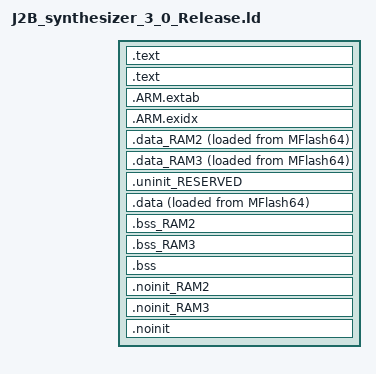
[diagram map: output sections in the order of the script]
/*
 * GENERATED FILE - DO NOT EDIT
 * (c) Code Red Technologies Ltd, 2008-${year}
 * (c) NXP Semiconductors 2013-${year}
 * Generated linker script file for 2015
 * Created from LPC1347 (Wed May 06 22:53:42 CEST 2015)
 * By generic_c.ld on LPCXpresso v7.0.2 [Build 102] [2014-03-11] 
 */


INCLUDE "J2B_synthesizer_3_0_Release_lib.ld"
INCLUDE "J2B_synthesizer_3_0_Release_mem.ld"

ENTRY(ResetISR)

SECTIONS
{

    /* MAIN TEXT SECTION */    
    .text : ALIGN(4)
    {
        FILL(0xff)
        __vectors_start__ = ABSOLUTE(.) ;
        KEEP(*(.isr_vector))
        
        /* Global Section Table */
        . = ALIGN(4) ;
        __section_table_start = .;
        __data_section_table = .;
        LONG(LOADADDR(.data));
        LONG(    ADDR(.data));
        LONG(  SIZEOF(.data));
        LONG(LOADADDR(.data_RAM2));
        LONG(    ADDR(.data_RAM2));
        LONG(  SIZEOF(.data_RAM2));
        LONG(LOADADDR(.data_RAM3));
        LONG(    ADDR(.data_RAM3));
        LONG(  SIZEOF(.data_RAM3));
        __data_section_table_end = .;
        __bss_section_table = .;
        LONG(    ADDR(.bss));
        LONG(  SIZEOF(.bss));
        LONG(    ADDR(.bss_RAM2));
        LONG(  SIZEOF(.bss_RAM2));
        LONG(    ADDR(.bss_RAM3));
        LONG(  SIZEOF(.bss_RAM3));
        __bss_section_table_end = .;
        __section_table_end = . ;
        /* End of Global Section Table */
        

        *(.after_vectors*)
        
    } >MFlash64
    
    .text : ALIGN(4)    
    {
         *(.text*)
        *(.rodata .rodata.* .constdata .constdata.*)
        . = ALIGN(4);
        
    } > MFlash64

    /*
     * for exception handling/unwind - some Newlib functions (in common
     * with C++ and STDC++) use this. 
     */
    .ARM.extab : ALIGN(4)
    {
    	*(.ARM.extab* .gnu.linkonce.armextab.*)
    } > MFlash64
    __exidx_start = .;
    
    .ARM.exidx : ALIGN(4)
    {
    	*(.ARM.exidx* .gnu.linkonce.armexidx.*)
    } > MFlash64
    __exidx_end = .;
    
    _etext = .;
        
    
    /* DATA section for RamUsb2 */
    .data_RAM2 : ALIGN(4)
    {
       FILL(0xff)
       *(.ramfunc.$RAM2)
    	*(.data.$RAM2*)
    	*(.data.$RamUsb2*)
       . = ALIGN(4) ;
    } > RamUsb2 AT>MFlash64
    
    /* DATA section for RamPeriph2 */
    .data_RAM3 : ALIGN(4)
    {
       FILL(0xff)
       *(.ramfunc.$RAM3)
    	*(.data.$RAM3*)
    	*(.data.$RamPeriph2*)
       . = ALIGN(4) ;
    } > RamPeriph2 AT>MFlash64
    
    /* MAIN DATA SECTION */
    

    .uninit_RESERVED : ALIGN(4)
    {
        KEEP(*(.bss.$RESERVED*))
        . = ALIGN(4) ;
        _end_uninit_RESERVED = .;
    } > RamLoc8

	
	/* Main DATA section (RamLoc8) */
	.data : ALIGN(4)
	{
	   FILL(0xff)
	   _data = . ;
	   *(vtable)
	   *(.ramfunc*)
	   *(.data*)
	   . = ALIGN(4) ;
	   _edata = . ;
	} > RamLoc8 AT>MFlash64

    /* BSS section for RamUsb2 */
    .bss_RAM2 : ALIGN(4)
    {
    	*(.bss.$RAM2*)
    	*(.bss.$RamUsb2*)
       . = ALIGN(4) ;
    } > RamUsb2
    /* BSS section for RamPeriph2 */
    .bss_RAM3 : ALIGN(4)
    {
    	*(.bss.$RAM3*)
    	*(.bss.$RamPeriph2*)
       . = ALIGN(4) ;
    } > RamPeriph2

    /* MAIN BSS SECTION */
    .bss : ALIGN(4)
    {
        _bss = .;
        *(.bss*)
        *(COMMON)
        . = ALIGN(4) ;
        _ebss = .;
        PROVIDE(end = .);
    } > RamLoc8
        
    /* NOINIT section for RamUsb2 */
    .noinit_RAM2 (NOLOAD) : ALIGN(4)
    {
    	*(.noinit.$RAM2*)
    	*(.noinit.$RamUsb2*)
       . = ALIGN(4) ;
    } > RamUsb2 
    /* NOINIT section for RamPeriph2 */
    .noinit_RAM3 (NOLOAD) : ALIGN(4)
    {
    	*(.noinit.$RAM3*)
    	*(.noinit.$RamPeriph2*)
       . = ALIGN(4) ;
    } > RamPeriph2 
    
    /* DEFAULT NOINIT SECTION */
    .noinit (NOLOAD): ALIGN(4)
    {
        _noinit = .;
        *(.noinit*) 
         . = ALIGN(4) ;
        _end_noinit = .;
    } > RamLoc8
    
    PROVIDE(_pvHeapStart = .);
    PROVIDE(_vStackTop = __top_RamLoc8 - 0);
}
